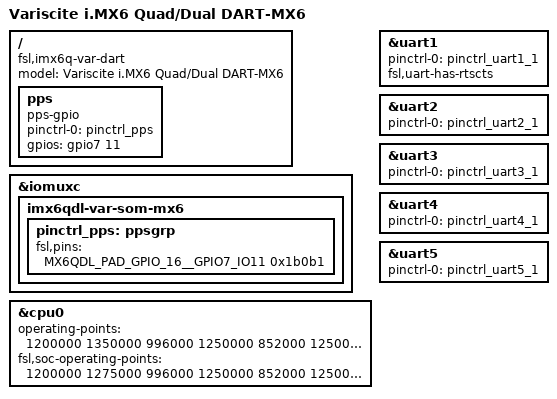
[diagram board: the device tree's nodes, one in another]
/*
 * Copyright (C) 2015-2017 Variscite Ltd.
 *
 * This program is free software; you can redistribute it and/or modify
 * it under the terms of the GNU General Public License version 2 as
 * published by the Free Software Foundation.
 */

/dts-v1/;

#include "imx6q.dtsi"
#include "imx6qdl-iris2.dtsi"
#include "imx6q-iris2-low-power.dtsi"

/ {
	model = "Variscite i.MX6 Quad/Dual DART-MX6";
	compatible = "fsl,imx6q-var-dart", "fsl,imx6q";

	pps {
		compatible = "pps-gpio";
		pinctrl-names = "default";
		pinctrl-0 = <&pinctrl_pps>;
		gpios = <&gpio7 11 GPIO_ACTIVE_HIGH>;
		status = "okay";
	};
};

&iomuxc {
	imx6qdl-var-som-mx6 {
		pinctrl_pps: ppsgrp {
			fsl,pins = <
				MX6QDL_PAD_GPIO_16__GPIO7_IO11	0x1b0b1	/* 100K PU, HYS, KEEPER, FAST */
			>;
		};
	};
};

&cpu0 {
	operating-points = <
		/* kHz    uV */
		1200000	1350000
		996000	1250000
		852000	1250000
		792000	1175000
		396000	1175000
	>;
	fsl,soc-operating-points = <
		/* ARM kHz  SOC-PU uV */
		1200000	1275000
		996000	1250000
		852000	1250000
		792000	1250000
		396000	1250000
	>;
};

/* ttymxc0 UART (Console) */
&uart1 {
	pinctrl-names = "default";
	pinctrl-0 = <&pinctrl_uart1_1>;
	fsl,uart-has-rtscts;
	status = "okay";
};

/* ttymxc1 UART (External) */
&uart2 {
	pinctrl-names = "default";
	pinctrl-0 = <&pinctrl_uart2_1>;
	status = "okay";
};

/* ttymxc2 UART (PDDL) */
&uart3 {
	pinctrl-names = "default";
	pinctrl-0 = <&pinctrl_uart3_1>;
	status = "okay";
};

/* ttymxc3 UART (Pixhawk) */
&uart4 {
	pinctrl-names = "default";
	pinctrl-0 = <&pinctrl_uart4_1>;
	status = "okay";
};

/* ttymxc4 UART (Iridium) */
&uart5 {
	pinctrl-names = "default";
	pinctrl-0 = <&pinctrl_uart5_1>;
	status = "okay";
};
